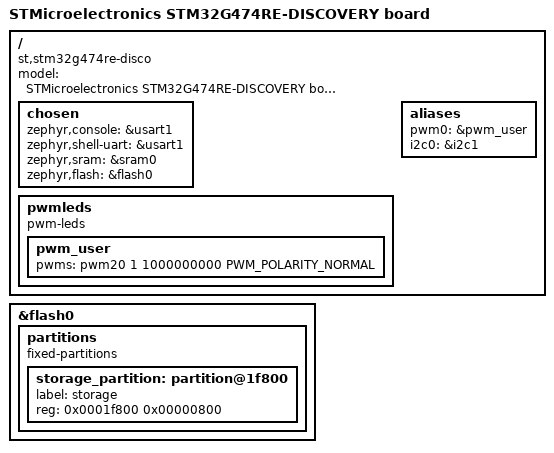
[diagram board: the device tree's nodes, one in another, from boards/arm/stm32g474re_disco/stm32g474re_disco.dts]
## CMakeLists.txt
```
# SPDX-License-Identifier: Apache-2.0

cmake_minimum_required(VERSION 3.13.1)

set(PROJ_ROOT ${CMAKE_CURRENT_SOURCE_DIR}/)
set(DTS_ROOT ${CMAKE_CURRENT_SOURCE_DIR}/dts)
#set(DTC_OVERLAY_FILE "boards/stm32g474re_disco.overlay")

set(BOARD_ROOT ${CMAKE_CURRENT_LIST_DIR})
set(BOARD stm32g474re_disco)

find_package(Zephyr REQUIRED HINTS $ENV{ZEPHYR_BASE})
project(pwm_test)

target_sources(app PRIVATE src/main.c)
```

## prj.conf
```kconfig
CONFIG_STDOUT_CONSOLE=y
CONFIG_PRINTK=y
CONFIG_PWM=y
CONFIG_LOG=y
CONFIG_LOG_PRINTK=y
#CONFIG_LOG_IMMEDIATE=y
CONFIG_PWM_LOG_LEVEL_DBG=y
```

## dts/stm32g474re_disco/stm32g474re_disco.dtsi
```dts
/*
 * Copyright (c) 2020 Rohan Dey
 *
 * SPDX-License-Identifier: Apache-2.0
 */

#include "acme_cpu_c201_usart1.dtsi"
/*#include "stm32g474re_disco_usart3.dtsi"*/
#include "stm32g474re_disco_timers20.dtsi"
/*#include "acme_cpu_c201_timers3.dtsi"*/
```

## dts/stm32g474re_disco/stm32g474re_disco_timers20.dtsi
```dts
/*
 * Copyright (c) 2020 Rohan Dey
 *
 * SPDX-License-Identifier: Apache-2.0
 */

#include <dt-bindings/pinctrl/stm32-pinctrl.h>
#include <st/g4/stm32g473r(b-c-e)tx-pinctrl.dtsi>

&pinctrl {

  tim20_ch1: gpiob_2 {
    pinmux = <STM32_PINMUX('B', 2, AF3)>;
  };

};

&timers20 {
  status = "okay";
  pwm20: pwm {
    status = "okay";
    pinctrl-0 = <&tim20_ch1>;
    st,prescaler = <10000>;
    #pwm-cells = <3>;
  };
};
```

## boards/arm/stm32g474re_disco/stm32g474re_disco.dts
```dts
/*
 * Copyright (c) 2019 STMicroelectronics.
 *
 * SPDX-License-Identifier: Apache-2.0
 */

/dts-v1/;
#include <st/g4/stm32g473Xe.dtsi>
#include <st/g4/stm32g474r(b-c-e)tx-pinctrl.dtsi>
#include <stm32g474re_disco/stm32g474re_disco.dtsi>

/ {
	model = "STMicroelectronics STM32G474RE-DISCOVERY board";
	compatible = "st,stm32g474re-disco";

	chosen {
		zephyr,console = &usart1;
		zephyr,shell-uart = &usart1;
		zephyr,sram = &sram0;
		zephyr,flash = &flash0;
	};
	
	pwmleds {
		compatible = "pwm-leds";
		pwm_user: pwm_user {
			pwms = <&pwm20 1 1000000000 PWM_POLARITY_NORMAL>;
			/*pwms = <&pwm3 1 1000000000 PWM_POLARITY_NORMAL>;*/
		};
	};
	
	aliases {
		pwm0 = &pwm_user;
		i2c0 = &i2c1;
	};
};

&flash0 {
	/*
	 * For more information, see:
	 * http://docs.zephyrproject.org/latest/guides/dts/index.html#flash-partitions
	 */
	partitions {
		compatible = "fixed-partitions";
		#address-cells = <1>;
		#size-cells = <1>;

		/* Set 2Kb of storage at the end of the 128Kb of flash */
		storage_partition: partition@1f800 {
			label = "storage";
			reg = <0x0001f800 0x00000800>;
		};
	};
};
```

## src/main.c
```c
/**
 * @file Sample app to demonstrate PWM.
 */

#include <zephyr.h>
#include <sys/printk.h>
#include <device.h>
#include <drivers/pwm.h>

#define PWM_BUZZER_NODE	DT_ALIAS(pwm0)

#if DT_NODE_HAS_STATUS(PWM_BUZZER_NODE, okay)
#define PWM_LABEL	DT_PWMS_LABEL(PWM_BUZZER_NODE)
#define PWM_CHANNEL	DT_PWMS_CHANNEL(PWM_BUZZER_NODE)
#define PWM_FLAGS	DT_PWMS_FLAGS(PWM_BUZZER_NODE)
#else
#error "Unsupported board: pwm0 devicetree alias is not defined"
#define PWM_LABEL	""
#define PWM_CHANNEL	0
#define PWM_FLAGS	0
#endif

#define SINGLE_TONE	1
//#define TUNE_1	1

void main(void) {
	const struct device *pwm;
	uint32_t period = 0;
	uint32_t offset = 1000;
	int ret;

	printk("PWM-based buzzer\n");

	pwm = device_get_binding(PWM_LABEL);
	if (!pwm) {
		printk("Error: didn't find %s device\n", PWM_LABEL);
		return;
	}

#if SINGLE_TONE
	uint32_t period_4k = (1*1000*1000)/4000;	// 4000 Hz, period in usecs
	bool toggle = 1;
#endif

	while (1) {
#if SINGLE_TONE
		if (toggle)
			period = period_4k;
		else
			period = 0;

		printk("Setting pwm period to %d usec\n", period);

		ret = pwm_pin_set_usec(pwm, PWM_CHANNEL, period, period / 2U, PWM_FLAGS);
		if (ret) {
			printk("Error %d: failed to set pulse width\n", ret);
			return;
		}

		toggle = !toggle;
		k_sleep(K_MSEC(500));

#elif TUNE_1
		for (int i=0; i<8; i++) {
			printk("Setting pwm period to %d usec\n", period);
			ret = pwm_pin_set_usec(pwm, PWM_CHANNEL, period, period / 2U, PWM_FLAGS);
			if (ret) {
				printk("Error %d: failed to set pulse width\n", ret);
				return;
			}
			k_sleep(K_MSEC(100));

			period = (1*1000*1000)/offset;
			offset += 1000;
		}

		period = 0;			// reset period
		offset = 1000;		// reset offset
#else

#endif
	}
}
```
